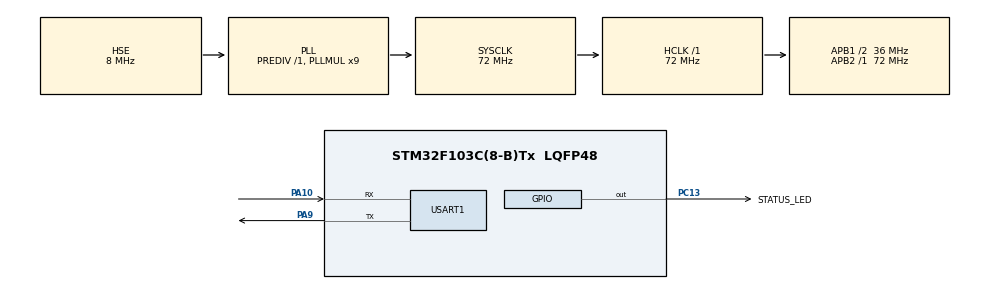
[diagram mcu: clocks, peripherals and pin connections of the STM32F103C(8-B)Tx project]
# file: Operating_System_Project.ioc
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FREERTOS.Tasks01=bootstrapTask,24,128,StartBootstrapTask,Default,NULL,Dynamic,NULL,NULL
FREERTOS.configCHECK_FOR_STACK_OVERFLOW=2
FREERTOS.configTOTAL_HEAP_SIZE=8192
FREERTOS.configUSE_MALLOC_FAILED_HOOK=1
Mcu.Family=STM32F1
Mcu.Name=STM32F103C(8-B)Tx
Mcu.Package=LQFP48
NVIC.PriorityGroup=NVIC_PRIORITYGROUP_4
NVIC.TIM4_IRQn=true\:15\:0\:false\:false\:true\:false\:false\:true\:true
NVIC.TimeBase=TIM4_IRQn
NVIC.TimeBaseIP=TIM4
NVIC.USART1_IRQn=true\:6\:0\:true\:false\:true\:true\:true\:true\:true
PA10.Mode=Asynchronous
PA10.Signal=USART1_RX
PA13.Mode=Serial_Wire
PA13.Signal=SYS_JTMS-SWDIO
PA14.Mode=Serial_Wire
PA14.Signal=SYS_JTCK-SWCLK
PA9.Mode=Asynchronous
PA9.Signal=USART1_TX
PC13-TAMPER-RTC.GPIO_Label=STATUS_LED
PC13-TAMPER-RTC.GPIO_ModeDefaultOutputPP=GPIO_MODE_OUTPUT_PP
PC13-TAMPER-RTC.GPIO_PuPd=GPIO_NOPULL
PC13-TAMPER-RTC.PinState=GPIO_PIN_SET
PC13-TAMPER-RTC.Signal=GPIO_Output
PD0-OSC_IN.Mode=HSE-External-Oscillator
PD0-OSC_IN.Signal=RCC_OSC_IN
PD1-OSC_OUT.Mode=HSE-External-Oscillator
PD1-OSC_OUT.Signal=RCC_OSC_OUT
ProjectManager.HeapSize=0x200
ProjectManager.StackSize=0x400
ProjectManager.TargetToolchain=MDK-ARM V5.32
RCC.AHBFreq_Value=72000000
RCC.APB1CLKDivider=RCC_HCLK_DIV2
RCC.APB1Freq_Value=36000000
RCC.APB1TimFreq_Value=72000000
RCC.APB2Freq_Value=72000000
RCC.APB2TimFreq_Value=72000000
RCC.HCLKFreq_Value=72000000
RCC.PLLMUL=RCC_PLL_MUL9
RCC.PLLSourceVirtual=RCC_PLLSOURCE_HSE
RCC.SYSCLKFreq_VALUE=72000000
RCC.SYSCLKSource=RCC_SYSCLKSOURCE_PLLCLK
RCC.USBFreq_Value=72000000
USART1.VirtualMode=VM_ASYNC
VP_FREERTOS_VS_CMSIS_V2.Mode=CMSIS_V2
VP_SYS_VS_tim4.Mode=TIM4
board=custom

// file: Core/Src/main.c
/* USER CODE BEGIN Header */
/**
  ******************************************************************************
  * @file           : main.c
  * @brief          : Main program body
  ******************************************************************************
  * @attention
  *
  * Copyright (c) 2026 STMicroelectronics.
  * All rights reserved.
  *
  * This software is licensed under terms that can be found in the LICENSE file
  * in the root directory of this software component.
  * If no LICENSE file comes with this software, it is provided AS-IS.
  *
  ******************************************************************************
  */
/* USER CODE END Header */
#include "main.h"
#include "cmsis_os.h"

/* USER CODE BEGIN Includes */
#include "rtsfr_m5_config.h"
#include "m5_command.h"
#include "iwdg.h"
#if (configRTSFR_M4_TARGET_TEST == 1)
#include "test_m4.h"
#endif

/* USER CODE END Includes */

UART_HandleTypeDef huart1;

/* Definitions for bootstrapTask */
osThreadId_t bootstrapTaskHandle;
const osThreadAttr_t bootstrapTask_attributes = {
  .name = "bootstrapTask",
  .stack_size = (configRTSFR_M5_ENABLE ? 512 : 128) * 4,
  .priority = (osPriority_t) osPriorityNormal,
};

void SystemClock_Config(void);
static void MX_GPIO_Init(void);
static void MX_USART1_UART_Init(void);
void StartBootstrapTask(void *argument);

int main(void)
{

  /* MCU Configuration--------------------------------------------------------*/

  /* Reset of all peripherals, Initializes the Flash interface and the Systick. */
  HAL_Init();

  /* Configure the system clock */
  SystemClock_Config();

  /* Initialize all configured peripherals */
  MX_GPIO_Init();
  MX_USART1_UART_Init();
  /* USER CODE BEGIN 2 */
#if configRTSFR_M5_ENABLE
  rtsfr_iwdg_capture_reset_cause();
#endif

  /* USER CODE END 2 */

  /* Init scheduler */
  osKernelInitialize();

  /* Create the thread(s) */
  /* creation of bootstrapTask */
  bootstrapTaskHandle = osThreadNew(StartBootstrapTask, NULL, &bootstrapTask_attributes);

  /* Start scheduler */
  osKernelStart();

  /* We should never get here as control is now taken by the scheduler */

  /* Infinite loop */
  while (1)
  {

  }
}

void SystemClock_Config(void)
{
  RCC_OscInitTypeDef RCC_OscInitStruct = {0};
  RCC_ClkInitTypeDef RCC_ClkInitStruct = {0};

  /** Initializes the RCC Oscillators according to the specified parameters
  * in the RCC_OscInitTypeDef structure.
  */
  RCC_OscInitStruct.OscillatorType = RCC_OSCILLATORTYPE_HSE;
  RCC_OscInitStruct.HSEState = RCC_HSE_ON;
  RCC_OscInitStruct.HSEPredivValue = RCC_HSE_PREDIV_DIV1;
  RCC_OscInitStruct.HSIState = RCC_HSI_ON;
  RCC_OscInitStruct.PLL.PLLState = RCC_PLL_ON;
  RCC_OscInitStruct.PLL.PLLSource = RCC_PLLSOURCE_HSE;
  RCC_OscInitStruct.PLL.PLLMUL = RCC_PLL_MUL9;
  if (HAL_RCC_OscConfig(&RCC_OscInitStruct) != HAL_OK)
  {
    Error_Handler();
  }

  /** Initializes the CPU, AHB and APB buses clocks
  */
  RCC_ClkInitStruct.ClockType = RCC_CLOCKTYPE_HCLK|RCC_CLOCKTYPE_SYSCLK
                              |RCC_CLOCKTYPE_PCLK1|RCC_CLOCKTYPE_PCLK2;
  RCC_ClkInitStruct.SYSCLKSource = RCC_SYSCLKSOURCE_PLLCLK;
  RCC_ClkInitStruct.AHBCLKDivider = RCC_SYSCLK_DIV1;
  RCC_ClkInitStruct.APB1CLKDivider = RCC_HCLK_DIV2;
  RCC_ClkInitStruct.APB2CLKDivider = RCC_HCLK_DIV1;

  if (HAL_RCC_ClockConfig(&RCC_ClkInitStruct, FLASH_LATENCY_2) != HAL_OK)
  {
    Error_Handler();
  }
}

static void MX_USART1_UART_Init(void)
{

  huart1.Instance = USART1;
  huart1.Init.BaudRate = 115200;
  huart1.Init.WordLength = UART_WORDLENGTH_8B;
  huart1.Init.StopBits = UART_STOPBITS_1;
  huart1.Init.Parity = UART_PARITY_NONE;
  huart1.Init.Mode = UART_MODE_TX_RX;
  huart1.Init.HwFlowCtl = UART_HWCONTROL_NONE;
  huart1.Init.OverSampling = UART_OVERSAMPLING_16;
  if (HAL_UART_Init(&huart1) != HAL_OK)
  {
    Error_Handler();
  }

}

static void MX_GPIO_Init(void)
{
  GPIO_InitTypeDef GPIO_InitStruct = {0};

  /* GPIO Ports Clock Enable */
  __HAL_RCC_GPIOC_CLK_ENABLE();
  __HAL_RCC_GPIOD_CLK_ENABLE();
  __HAL_RCC_GPIOA_CLK_ENABLE();

  /*Configure GPIO pin Output Level */
  HAL_GPIO_WritePin(STATUS_LED_GPIO_Port, STATUS_LED_Pin, GPIO_PIN_SET);

  /*Configure GPIO pin : STATUS_LED_Pin */
  GPIO_InitStruct.Pin = STATUS_LED_Pin;
  GPIO_InitStruct.Mode = GPIO_MODE_OUTPUT_PP;
  GPIO_InitStruct.Pull = GPIO_NOPULL;
  GPIO_InitStruct.Speed = GPIO_SPEED_FREQ_LOW;
  HAL_GPIO_Init(STATUS_LED_GPIO_Port, &GPIO_InitStruct);

}

void StartBootstrapTask(void *argument)
{
  /* USER CODE BEGIN 5 */
  /* Infinite loop */
  (void)argument;
#if configRTSFR_M5_ENABLE
  rtsfr_m5_service_init();
#endif

#if (configRTSFR_M4_TARGET_TEST == 1)
  rtsfr_m4_target_test_run();
#endif

  for (;;)
  {
    HAL_GPIO_TogglePin(STATUS_LED_GPIO_Port,
                       STATUS_LED_Pin);

    /* M5 handles UART outside kernel hooks and blocks between polls. */
#if configRTSFR_M5_ENABLE
    for (unsigned int m5_poll = 0U; m5_poll < 250U; ++m5_poll) {
      rtsfr_m5_service_poll();
      osDelay(2);
    }
#else
    osDelay(500);
#endif
  }
  /* USER CODE END 5 */
}

void HAL_TIM_PeriodElapsedCallback(TIM_HandleTypeDef *htim)
{
  if (htim->Instance == TIM4)
  {
    HAL_IncTick();
  }
}

void Error_Handler(void)
{
  __disable_irq();
  while (1)
  {
  }
}

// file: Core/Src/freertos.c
/* USER CODE BEGIN Header */
/**
  ******************************************************************************
  * File Name          : freertos.c
  * Description        : Code for freertos applications
  ******************************************************************************
  * @attention
  *
  * Copyright (c) 2026 STMicroelectronics.
  * All rights reserved.
  *
  * This software is licensed under terms that can be found in the LICENSE file
  * in the root directory of this software component.
  * If no LICENSE file comes with this software, it is provided AS-IS.
  *
  ******************************************************************************
  */
/* USER CODE END Header */

#include "FreeRTOS.h"
#include "task.h"
#include "main.h"
#include "cmsis_os.h"

/* Definitions for defaultTask */
osThreadId_t defaultTaskHandle;
const osThreadAttr_t defaultTask_attributes = {
  .name = "defaultTask",
  .stack_size = 128 * 4,
  .priority = (osPriority_t) osPriorityNormal,
};

void StartDefaultTask(void *argument);

void MX_FREERTOS_Init(void); /* (MISRA C 2004 rule 8.1) */

/* Hook prototypes */
void vApplicationMallocFailedHook(void);

/* USER CODE BEGIN 5 */
void vApplicationMallocFailedHook(void)
{
   /* vApplicationMallocFailedHook() will only be called if
   configUSE_MALLOC_FAILED_HOOK is set to 1 in FreeRTOSConfig.h. It is a hook
   function that will get called if a call to pvPortMalloc() fails.
   pvPortMalloc() is called internally by the kernel whenever a task, queue,
   timer or semaphore is created. It is also called by various parts of the
   demo application. If heap_1.c or heap_2.c are used, then the size of the
   heap available to pvPortMalloc() is defined by configTOTAL_HEAP_SIZE in
   FreeRTOSConfig.h, and the xPortGetFreeHeapSize() API function can be used
   to query the size of free heap space that remains (although it does not
   provide information on how the remaining heap might be fragmented). */
}
/* USER CODE END 5 */

void MX_FREERTOS_Init(void) {

  /* Create the thread(s) */
  /* creation of defaultTask */
  defaultTaskHandle = osThreadNew(StartDefaultTask, NULL, &defaultTask_attributes);

}

void StartDefaultTask(void *argument)
{
  for(;;)
  {
    osDelay(1);
  }
}
